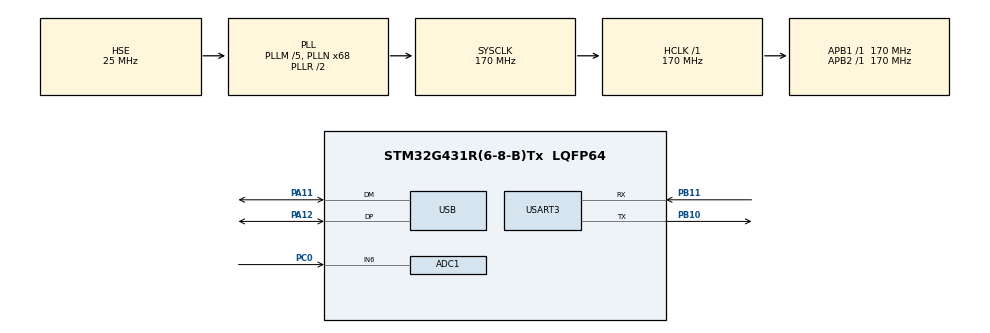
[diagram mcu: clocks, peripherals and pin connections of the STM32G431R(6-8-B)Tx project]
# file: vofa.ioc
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ADC1.Channel-0\#ChannelRegularConversion=ADC_CHANNEL_6
ADC1.EnableInjectedConversion=ENABLE
ADC1.ExternalTrigInjecConv=ADC_EXTERNALTRIGINJEC_T1_CC4
ADC1.InjNumberOfConversion=1
ADC1.InjectedChannel-1\#ChannelInjectedConversion=ADC_CHANNEL_6
ADC1.InjectedOffsetNumber-1\#ChannelInjectedConversion=ADC_OFFSET_NONE
ADC1.InjectedRank-1\#ChannelInjectedConversion=1
ADC1.InjectedSamplingTime-1\#ChannelInjectedConversion=ADC_SAMPLETIME_47CYCLES_5
ADC1.NbrOfConversionFlag=1
ADC1.OffsetNumber-0\#ChannelRegularConversion=ADC_OFFSET_NONE
ADC1.Rank-0\#ChannelRegularConversion=1
ADC1.Rank1_Channel=ADC_CHANNEL_6
ADC1.SamplingTime-0\#ChannelRegularConversion=ADC_SAMPLETIME_2CYCLES_5
ADC1.master=1
Mcu.Family=STM32G4
Mcu.Name=STM32G431R(6-8-B)Tx
Mcu.Package=LQFP64
NVIC.ADC1_2_IRQn=true\:0\:0\:false\:false\:true\:true\:true\:true
NVIC.PriorityGroup=NVIC_PRIORITYGROUP_4
NVIC.USB_LP_IRQn=true\:0\:0\:false\:false\:true\:false\:true\:true
PA11.Mode=Device
PA11.Signal=USB_DM
PA12.Mode=Device
PA12.Signal=USB_DP
PA13.Mode=Serial_Wire
PA13.Signal=SYS_JTMS-SWDIO
PA14.Mode=Serial_Wire
PA14.Signal=SYS_JTCK-SWCLK
PB10.Mode=Asynchronous
PB10.Signal=USART3_TX
PB11.Mode=Asynchronous
PB11.Signal=USART3_RX
PC0.Mode=IN6-Single-Ended
PC0.Signal=ADC1_IN6
PF0-OSC_IN.Mode=HSE-External-Oscillator
PF0-OSC_IN.Signal=RCC_OSC_IN
PF1-OSC_OUT.Mode=HSE-External-Oscillator
PF1-OSC_OUT.Signal=RCC_OSC_OUT
ProjectManager.HeapSize=0x200
ProjectManager.StackSize=0x400
ProjectManager.TargetToolchain=MDK-ARM V5.32
RCC.ADC12Freq_Value=170000000
RCC.AHBFreq_Value=170000000
RCC.APB1Freq_Value=170000000
RCC.APB1TimFreq_Value=170000000
RCC.APB2Freq_Value=170000000
RCC.APB2TimFreq_Value=170000000
RCC.CK48CLockSelection=RCC_USBCLKSOURCE_HSI48
RCC.CortexFreq_Value=170000000
RCC.EXTERNAL_CLOCK_VALUE=12288000
RCC.HCLKFreq_Value=170000000
RCC.HSE_VALUE=25000000
RCC.HSI48_VALUE=48000000
RCC.HSI_VALUE=16000000
RCC.LSE_VALUE=32768
RCC.PLLM=RCC_PLLM_DIV5
RCC.PLLN=68
RCC.PLLQ=RCC_PLLQ_DIV6
RCC.PLLSourceVirtual=RCC_PLLSOURCE_HSE
RCC.SYSCLKFreq_VALUE=170000000
RCC.SYSCLKSource=RCC_SYSCLKSOURCE_PLLCLK
RCC.USBFreq_Value=48000000
RCC.VCOOutputFreq_Value=340000000
TIM1.Channel-PWM\ Generation4\ No\ Output=TIM_CHANNEL_4
TIM1.PeriodNoDither=8500
TIM1.PulseNoDither_4=5
USART3.VirtualMode-Asynchronous=VM_ASYNC
USB_DEVICE.CLASS_NAME_FS=CDC
USB_DEVICE.VirtualMode=Cdc
USB_DEVICE.VirtualModeFS=Cdc_FS
VP_SYS_VS_DBSignals.Mode=DisableDeadBatterySignals
VP_TIM1_VS_no_output4.Mode=PWM Generation4 No Output
VP_USB_DEVICE_VS_USB_DEVICE_CDC_FS.Mode=CDC_FS
board=custom

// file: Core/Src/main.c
/* USER CODE BEGIN Header */
/**
  ******************************************************************************
  * @file           : main.c
  * @brief          : Main program body
  ******************************************************************************
  * @attention
  *
  * Copyright (c) 2023 STMicroelectronics.
  * All rights reserved.
  *
  * This software is licensed under terms that can be found in the LICENSE file
  * in the root directory of this software component.
  * If no LICENSE file comes with this software, it is provided AS-IS.
  *
  ******************************************************************************
  */
/* USER CODE END Header */
#include "main.h"
#include "adc.h"
#include "tim.h"
#include "usart.h"
#include "usb_device.h"
#include "gpio.h"

/* USER CODE BEGIN Includes */
#include "usbd_cdc_if.h"
#include "math.h"
#include "vofa.h"
/* USER CODE END Includes */

void SystemClock_Config(void);

int main(void)
{

  /* MCU Configuration--------------------------------------------------------*/

  /* Reset of all peripherals, Initializes the Flash interface and the Systick. */
  HAL_Init();

  /* USER CODE BEGIN Init */
	uint32_t time;
  /* USER CODE END Init */

  /* Configure the system clock */
  SystemClock_Config();

  /* Initialize all configured peripherals */
  MX_GPIO_Init();
  MX_USB_Device_Init();
  MX_ADC1_Init();
  MX_TIM1_Init();
  MX_USART3_UART_Init();
  /* USER CODE BEGIN 2 */
	HAL_TIM_PWM_Start(&htim1, TIM_CHANNEL_4);
	HAL_ADCEx_InjectedStart_IT(&hadc1);
  /* USER CODE END 2 */

  /* Infinite loop */
  /* USER CODE BEGIN WHILE */
  while (1)
  {

		vofa_start();

    /* USER CODE END WHILE */

  }
}

void SystemClock_Config(void)
{
  RCC_OscInitTypeDef RCC_OscInitStruct = {0};
  RCC_ClkInitTypeDef RCC_ClkInitStruct = {0};

  /** Configure the main internal regulator output voltage
  */
  HAL_PWREx_ControlVoltageScaling(PWR_REGULATOR_VOLTAGE_SCALE1_BOOST);

  /** Initializes the RCC Oscillators according to the specified parameters
  * in the RCC_OscInitTypeDef structure.
  */
  RCC_OscInitStruct.OscillatorType = RCC_OSCILLATORTYPE_HSI48|RCC_OSCILLATORTYPE_HSE;
  RCC_OscInitStruct.HSEState = RCC_HSE_ON;
  RCC_OscInitStruct.HSI48State = RCC_HSI48_ON;
  RCC_OscInitStruct.PLL.PLLState = RCC_PLL_ON;
  RCC_OscInitStruct.PLL.PLLSource = RCC_PLLSOURCE_HSE;
  RCC_OscInitStruct.PLL.PLLM = RCC_PLLM_DIV5;
  RCC_OscInitStruct.PLL.PLLN = 68;
  RCC_OscInitStruct.PLL.PLLP = RCC_PLLP_DIV2;
  RCC_OscInitStruct.PLL.PLLQ = RCC_PLLQ_DIV6;
  RCC_OscInitStruct.PLL.PLLR = RCC_PLLR_DIV2;
  if (HAL_RCC_OscConfig(&RCC_OscInitStruct) != HAL_OK)
  {
    Error_Handler();
  }

  /** Initializes the CPU, AHB and APB buses clocks
  */
  RCC_ClkInitStruct.ClockType = RCC_CLOCKTYPE_HCLK|RCC_CLOCKTYPE_SYSCLK
                              |RCC_CLOCKTYPE_PCLK1|RCC_CLOCKTYPE_PCLK2;
  RCC_ClkInitStruct.SYSCLKSource = RCC_SYSCLKSOURCE_PLLCLK;
  RCC_ClkInitStruct.AHBCLKDivider = RCC_SYSCLK_DIV1;
  RCC_ClkInitStruct.APB1CLKDivider = RCC_HCLK_DIV1;
  RCC_ClkInitStruct.APB2CLKDivider = RCC_HCLK_DIV1;

  if (HAL_RCC_ClockConfig(&RCC_ClkInitStruct, FLASH_LATENCY_4) != HAL_OK)
  {
    Error_Handler();
  }
}

/* USER CODE BEGIN 4 */
int i = 0;
void HAL_ADCEx_InjectedConvCpltCallback(ADC_HandleTypeDef *hadc)
{

	uint16_t adc_invalue = ADC1->JDR1;

//	vofa_start();

}
/* USER CODE END 4 */

void Error_Handler(void)
{
  __disable_irq();
  while (1)
  {
  }
}
